# CY8C5888LTI_LP097 register map
File version: 0.1
Registers are 8-bit, read-write, no defined reset value unless marked. A register's access mark holds for its fields unless they carry their own. Offsets are from the block's base; [hi:lo] are bit positions; {n}, {i} and the like mark numbered series; 'fields as' and 'values as' point back to an identical list.

## PWM_Steer
Base 0x00000000
0x4000642C PWM_Steer_COMPARE_Reg 16-bit — UDB.D0 - Assigned Compare Value
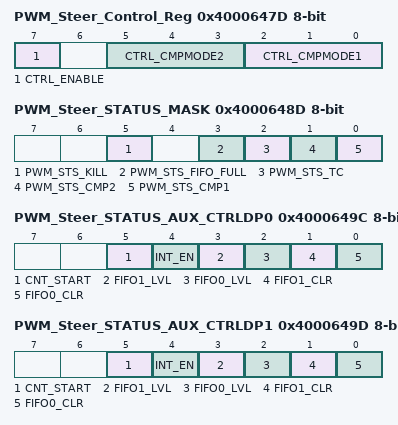
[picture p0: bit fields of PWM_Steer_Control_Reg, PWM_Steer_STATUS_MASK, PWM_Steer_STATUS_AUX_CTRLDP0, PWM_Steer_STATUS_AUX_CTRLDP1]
0x4000647D PWM_Steer_Control_Reg — UDB Control Register - Assigned Control Register Value
  [7] CTRL_ENABLE — Enable the PWM
  [5:3] CTRL_CMPMODE2 — Compare mode 2
  [2:0] CTRL_CMPMODE1 — Compare mode 1
0x4000648D PWM_Steer_STATUS_MASK — UDB Status bits Interrupt Mask Enable Register
  [5] PWM_STS_KILL ro — Enables the Interrupt on Kill
  [3] PWM_STS_FIFO_FULL ro — FIFO Full Status Mask
  [2] PWM_STS_TC ro — Enables the Interrupt on Terminal Count
  [1] PWM_STS_CMP2 ro — Enables the Interrupt on Compare 2
  [0] PWM_STS_CMP1 ro — Enables the Interrupt on Compare 1
0x4000649C PWM_Steer_STATUS_AUX_CTRLDP0 — UDB Auxilliary Control Register
  [5] CNT_START — FIFO0 clear
    0=E_CNT_START0 (Disable counter); 1=E_CNT_START1 (Enable counter)
  [4] INT_EN
    0=E_INT_EN0 (Interrupt disabled); 1=E_INT_EN1 (Interrupt enabled)
  [3] FIFO1_LVL — FIFO level
    0=E_FIFO_LVL_0 (FIFO LVL: input mode: FIFO not full; output mode: FIFO not empty); 1=E_FIFO_LVL_1 (FIFO LVL: input mode: FIFO at least 1/2 empty; output mode: FIFO at least 1/2 full)
  [2] FIFO0_LVL — FIFO level
    values as FIFO1_LVL
  [1] FIFO1_CLR — FIFO1 clear
    0=E_FIFO_CLR_0 (Normal FIFO operation); 1=E_FIFO_CLR_1 (Clear FIFO state)
  [0] FIFO0_CLR — FIFO0 clear
    values as FIFO1_CLR
0x4000649D PWM_Steer_STATUS_AUX_CTRLDP1 — UDB Auxilliary Control Register
  fields as PWM_Steer_STATUS_AUX_CTRLDP0

## SBUS_UART — UART
Base 0x00000000
0x40006525 RX_SBUS_UART_RX_ADDRESS1 — RX Address1 Register
0x40006535 RX_SBUS_UART_RX_ADDRESS2 — RX Address2 Register
0x40006545 RX_SBUS_UART_RX_DATA — RX Data Register
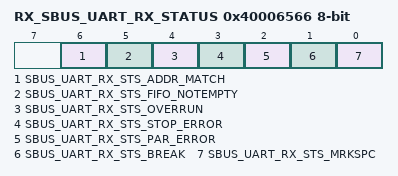
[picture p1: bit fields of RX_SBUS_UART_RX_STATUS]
0x40006566 RX_SBUS_UART_RX_STATUS — RX status register
  [6] SBUS_UART_RX_STS_ADDR_MATCH ro, [5] SBUS_UART_RX_STS_FIFO_NOTEMPTY ro, [4] SBUS_UART_RX_STS_OVERRUN ro, [3] SBUS_UART_RX_STS_STOP_ERROR ro, [2] SBUS_UART_RX_STS_PAR_ERROR ro, [1] SBUS_UART_RX_STS_BREAK ro, [0] SBUS_UART_RX_STS_MRKSPC ro

## Throttle
Base 0x00000000
0x400043A8 VDAC8_PM_ACT_CFG — Active Power Mode Configuration Register 8
  [4:0] en_dac — Enable DAC block(s). Populated subsystems are counted from the LSB
0x400043B8 VDAC8_PM_STBY_CFG — Standby Power Mode Configuration Register 8
  fields as VDAC8_PM_ACT_CFG
0x4000460B VDAC8_TR
  [7:0] tr — 8 Calibration bits
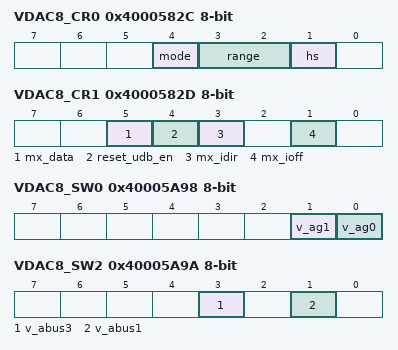
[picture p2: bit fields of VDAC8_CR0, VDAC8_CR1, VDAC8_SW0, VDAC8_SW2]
0x4000582C VDAC8_CR0 — DAC Block Control Register 0
  [4] mode ro — Mode Bit
    0=DAC_MODE_V (voltage DAC); 1=DAC_MODE_I (current DAC)
  [3:2] range — Ranges for mode=0 (VDAC) and mode=1 (IDAC)
    0=DAC_RANGE_0 (x0=0V to 4*vref (1.024V); 0 to 31.875uA); 1=DAC_RANGE_1 (x1=0V to 16*vref (4.096V); 0 to 255uA); 2=DAC_RANGE_2 (x0=0V to 4*vref (1.024V); 0 to 2.040mA); 3=DAC_RANGE_3 (x1=0V to 16*vref (4.096V); not used)
  [1] hs — High Speed Bit
    0=DAC_HS_LOWPOWER (regular (low power)); 1=DAC_HS_HIGHSPEED (high speed (higher power))
0x4000582D VDAC8_CR1 — DAC Block Control Register 1
  [5] mx_data — Select DATA source
    0=MX_DATA_REG (Select register source (DACxn_D)); 1=MX_DATA_UDB (Select UDB source)
  [4] reset_udb_en — DAC reset enable
    0=RESET_UDB_EN_DISABLE (Disable DAC Reset Source from UDB (System reset always resets)); 1=RESET_UDB_EN_ENABLE (Enable DAC Reset Source from UDB)
  [3] mx_idir — Mux selection for DAC current direction control
    0=MX_IDIR_REG (Register source idirbit selected); 1=MX_IDIR_UDB (UDB ictrl selected)
  [1] mx_ioff — Mux selection for DAC current off control
    0=MX_IOFF_REG (Register source ioffbit selected); 1=MX_IOFF_UDB (UDB ictrl selected)
0x40005A98 VDAC8_SW0 — DAC Analog Routing Register 0
  [1] v_ag1 — Connect voltage output to analog global of same side
    0=AG_NC (not connected); 1=AG_CONNECTED (Connect to Analog Global)
  [0] v_ag0 — Connect voltage output to analog global of same side
    values as v_ag1
0x40005A9A VDAC8_SW2 — DAC Analog Routing Register 2
  [3] v_abus3 — Connect voltage output to analog (local) bus of the same side
    0=ABUS_NC (not connected); 1=ABUS_CONNECTED (Connect to Analog (local) Bus)
  [1] v_abus1 — Connect voltage output to analog (local) bus of the same side
    values as v_abus3
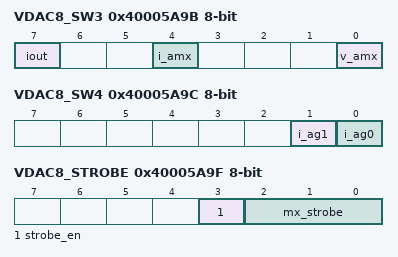
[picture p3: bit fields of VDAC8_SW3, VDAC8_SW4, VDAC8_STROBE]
0x40005A9B VDAC8_SW3 — DAC Analog Routing Register 3
  [7] iout — Connect current output to pad
    0=IOUT_NC (not connected); 1=IOUT_CONNECT (Connect to pad)
  [4] i_amx — Connect current output to Analog Mux Bus
    0=AMX_NC (not connected); 1=AMX_CONNECTED (Connect to AMUXBUS)
  [0] v_amx — Connect voltage output to Analog Mux Bus
    values as i_amx
0x40005A9C VDAC8_SW4 — DAC Analog Routing Register 4
  [1] i_ag1 — Connect current output to analog global of same side
    values as VDAC8_SW0.v_ag1
  [0] i_ag0 — Connect current output to analog global of same side
    values as VDAC8_SW0.v_ag1
0x40005A9F VDAC8_STROBE — DAC Strobe Register
  [3] strobe_en — Strobe gating control (See mx_strobe==3'h0)
    0=disable strobe; 1=enable strobe
  [2:0] mx_strobe — Strobe source selection
    0=MX_STROBE_BUSWRITE (Select bus write strobe source (Enable gater regardless of strobe_en setting)); 1=MX_STROBE_UDB_SRC (Select UDB strobe source); 2=MX_STROBE_NC_2 (NC); 3=MX_STROBE_NC_3 (NC); {v}=MX_STROBE_CLK_A{v-4}_DIG (Select clk_a{v-4}_dig) (v=4..7)
0x40005B83 VDAC8_DATA — DAC Data Register
  [7:0] data — 8 DAC Data bits

## Opamp_Throttle
Base 0x00000000
0x400043A4 PM_ACT_CFG4 — Active Power Mode Configuration Register 4
  [3:0] EN_OPAMP — Enables subsystems during active power mode
    0=Blk_0 (Enables analog linear output buffer for Opamp block 0); 2=Blk_1 (Enables analog linear output buffer for Opamp block 1); 4=Blk_2 (Enables analog linear output buffer for Opamp block 2); 8=Blk_3 (Enables analog linear output buffer for Opamp block 3)
0x400043B4 PM_STBY_CFG4 — Standby Power Mode Configuration Register 4
  [3:0] EN_OPAMP — Enables subsystems during standby power mode
    values as PM_ACT_CFG4.EN_OPAMP
0x40004626 OPAMP__TR0 — Analog Output Buffer Trim Register 0
  [4:0] offset_trim — Offset Trim: 420uV typical step size; +/- 6.8mV offset trimmable range
0x40004627 OPAMP__TR1 — Analog Output Buffer Trim Register 1
0x4000585E OPAMP__CR — Analog Output Buffer Configuration Register
  [1:0] pwr_mode — Power Mode
    0=Default_Fast (Default Power mode Fast); 1=Slow (Power Mode Slow); 2=Medium (Power Mode Medium); 3=Fast (Power Mode Fast)
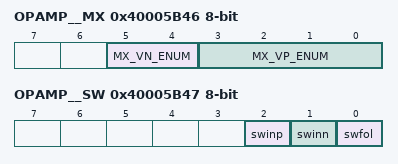
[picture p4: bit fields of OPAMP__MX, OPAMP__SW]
0x40005B46 OPAMP__MX — Analog Buffer Input Selection Register
  [5:4] MX_VN_ENUM — MUX select VN (Negative terminal input)
    0=OPAMP0_MX_VN_DEFAULT (Default - Not Connected (NC)); 1=OPAMP0_MX_VN_AG4 (MUX Selection AGL(4)); 2=OPAMP0_MX_VN_AG6 (MUX Selection AGL(6)); 3=OPAMP0_MX_VN_0x3 (Reserved (NC))
  [3:0] MX_VP_ENUM — MUX select VP (Positive terminal input)
    0=OPAMP0_MX_VP_DEFAULT (Default - Not Connected (NC)); {v}=OPAMP0_MX_VP_AG{v+3} (MUX Selection AGL({v+3})) (v=1..4); {v}=OPAMP0_MX_VP_ABUS{v-5} (MUX Selection ABUSL({v-5})) (v=5..8); 9=OPAMP0_MX_VP_VREF (MUX Selection: OPAMP Voltage Reference); {v}=OPAMP0_MX_VP_H_{0x0+v} (Reserved (NC)) (v=10..15)
0x40005B47 OPAMP__SW — Analog Buffer Routing Switch Register
  [2] swinp — Switch Enable Positive Input
  [1] swinn — Switch Enable Negative Input
  [0] swfol — Switch Enable Follow

## PWM_Brake
Base 0x00000000
0x4000642A PWM_Brake_COMPARE_Reg 16-bit — UDB.D0 - Assigned Compare Value
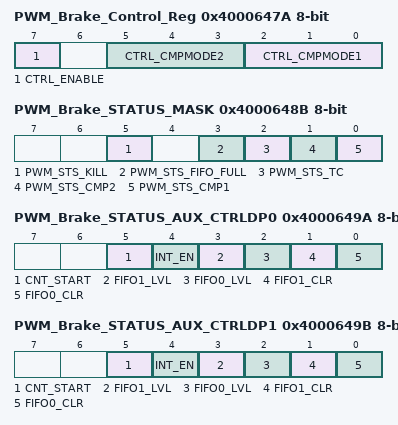
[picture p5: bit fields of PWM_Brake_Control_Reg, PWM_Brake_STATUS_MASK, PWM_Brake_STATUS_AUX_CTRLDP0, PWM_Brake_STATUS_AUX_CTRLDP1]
0x4000647A PWM_Brake_Control_Reg — UDB Control Register - Assigned Control Register Value
  [7] CTRL_ENABLE — Enable the PWM
  [5:3] CTRL_CMPMODE2 — Compare mode 2
  [2:0] CTRL_CMPMODE1 — Compare mode 1
0x4000648B PWM_Brake_STATUS_MASK — UDB Status bits Interrupt Mask Enable Register
  [5] PWM_STS_KILL ro — Enables the Interrupt on Kill
  [3] PWM_STS_FIFO_FULL ro — FIFO Full Status Mask
  [2] PWM_STS_TC ro — Enables the Interrupt on Terminal Count
  [1] PWM_STS_CMP2 ro — Enables the Interrupt on Compare 2
  [0] PWM_STS_CMP1 ro — Enables the Interrupt on Compare 1
0x4000649A PWM_Brake_STATUS_AUX_CTRLDP0 — UDB Auxilliary Control Register
  [5] CNT_START — FIFO0 clear
    0=E_CNT_START0 (Disable counter); 1=E_CNT_START1 (Enable counter)
  [4] INT_EN
    0=E_INT_EN0 (Interrupt disabled); 1=E_INT_EN1 (Interrupt enabled)
  [3] FIFO1_LVL — FIFO level
    0=E_FIFO_LVL_0 (FIFO LVL: input mode: FIFO not full; output mode: FIFO not empty); 1=E_FIFO_LVL_1 (FIFO LVL: input mode: FIFO at least 1/2 empty; output mode: FIFO at least 1/2 full)
  [2] FIFO0_LVL — FIFO level
    values as FIFO1_LVL
  [1] FIFO1_CLR — FIFO1 clear
    0=E_FIFO_CLR_0 (Normal FIFO operation); 1=E_FIFO_CLR_1 (Clear FIFO state)
  [0] FIFO0_CLR — FIFO0 clear
    values as FIFO1_CLR
0x4000649B PWM_Brake_STATUS_AUX_CTRLDP1 — UDB Auxilliary Control Register
  fields as PWM_Brake_STATUS_AUX_CTRLDP0
